# MCXC444 register map
Vendor: NXP Semiconductors; Series: MCX; File version: 1.6
CPU: CM0PLUS r0p0, little endian, no MPU, no FPU, VTOR, 2 interrupt priority bits
Registers are 32-bit, read-write, reset 0x0 unless marked. A register's access mark holds for its fields unless they carry their own. Offsets are from the block's base; [hi:lo] are bit positions; {n}, {i} and the like mark numbered series; 'fields as' and 'values as' point back to an identical list.

## PORTA — Pin Control and Interrupts
Base 0x40049000; register names take the prefix PORTA_
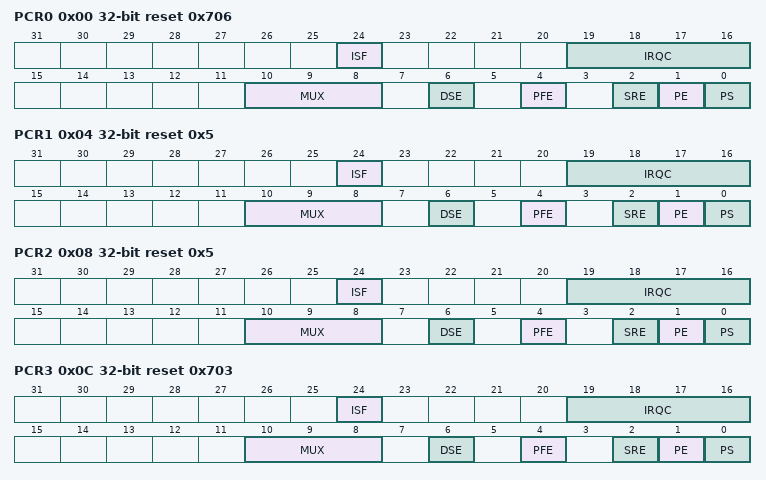
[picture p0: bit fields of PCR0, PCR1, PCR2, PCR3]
0x00 PCR0 reset 0x706 — Pin Control Register n
  [24] ISF — Interrupt Status Flag
    0=b0 (Configured interrupt is not detected.); 1=b1 (Configured interrupt is detected. If the pin is configured to generate a DMA request, then the corresponding flag will be cleared automatically at the completion of the requested DMA transfer. Otherwise, the flag remains set until a logic 1 is written to the flag. If the pin is configured for a level sensitive interrupt and the pin remains asserted, then the flag is set again immediately after it is cleared.)
  [19:16] IRQC — Interrupt Configuration
    0=b0000 (Interrupt/DMA request disabled.); 1=b0001 (DMA request on rising edge.); 2=b0010 (DMA request on falling edge.); 3=b0011 (DMA request on either edge.); 8=b1000 (Interrupt when logic 0.); 9=b1001 (Interrupt on rising-edge.); 10=b1010 (Interrupt on falling-edge.); 11=b1011 (Interrupt on either edge.); 12=b1100 (Interrupt when logic 1.)
  [10:8] MUX — Pin Mux Control
    0=b000 (Pin disabled (analog).); 1=b001 (Alternative 1 (GPIO).); 2=b010 (Alternative 2 (chip-specific).); 3=b011 (Alternative 3 (chip-specific).); 4=b100 (Alternative 4 (chip-specific).); 5=b101 (Alternative 5 (chip-specific).); 6=b110 (Alternative 6 (chip-specific).); 7=b111 (Alternative 7 (chip-specific).)
  [6] DSE ro — Drive Strength Enable
    0=b0 (Low drive strength is configured on the corresponding pin, if pin is configured as a digital output.); 1=b1 (High drive strength is configured on the corresponding pin, if pin is configured as a digital output.)
  [4] PFE ro — Passive Filter Enable
    0=b0 (Passive input filter is disabled on the corresponding pin.); 1=b1 (Passive input filter is enabled on the corresponding pin, if the pin is configured as a digital input. Refer to the device data sheet for filter characteristics.)
  [2] SRE — Slew Rate Enable
    0=b0 (Fast slew rate is configured on the corresponding pin, if the pin is configured as a digital output.); 1=b1 (Slow slew rate is configured on the corresponding pin, if the pin is configured as a digital output.)
  [1] PE — Pull Enable
    0=b0 (Internal pullup or pulldown resistor is not enabled on the corresponding pin.); 1=b1 (Internal pullup or pulldown resistor is enabled on the corresponding pin, if the pin is configured as a digital input.)
  [0] PS — Pull Select
    0=b0 (Internal pulldown resistor is enabled on the corresponding pin, if the corresponding PE field is set.); 1=b1 (Internal pullup resistor is enabled on the corresponding pin, if the corresponding PE field is set.)
0x04 PCR1 reset 0x5 — Pin Control Register n
  fields as PCR0
0x08 PCR2 reset 0x5 — Pin Control Register n
  fields as PCR0
0x0C PCR3 reset 0x703 — Pin Control Register n
  fields as PCR0
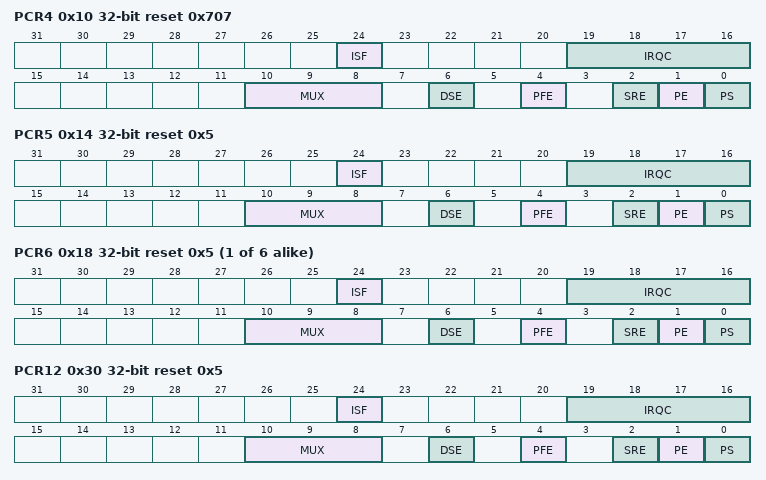
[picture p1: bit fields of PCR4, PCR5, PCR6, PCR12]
0x10 PCR4 reset 0x707 — Pin Control Register n
  [24] ISF — Interrupt Status Flag
    values as PCR0.ISF
  [19:16] IRQC — Interrupt Configuration
    values as PCR0.IRQC
  [10:8] MUX — Pin Mux Control
    values as PCR0.MUX
  [6] DSE ro — Drive Strength Enable
    values as PCR0.DSE
  [4] PFE — Passive Filter Enable
    values as PCR0.PFE
  [2] SRE — Slew Rate Enable
    values as PCR0.SRE
  [1] PE — Pull Enable
    values as PCR0.PE
  [0] PS — Pull Select
    values as PCR0.PS
0x14 PCR5 reset 0x5 — Pin Control Register n
  fields as PCR0
{0x0+4i} PCR{i} reset 0x5 (i=6..11) — Pin Control Register n
  [24] ISF — Interrupt Status Flag
    values as PCR0.ISF
  [19:16] IRQC — Interrupt Configuration
    values as PCR0.IRQC
  [10:8] MUX — Pin Mux Control
    values as PCR0.MUX
  [6] DSE ro — Drive Strength Enable
    values as PCR0.DSE
  [4] PFE ro — Passive Filter Enable
    values as PCR0.PFE
  [2] SRE ro — Slew Rate Enable
    values as PCR0.SRE
  [1] PE ro — Pull Enable
    values as PCR0.PE
  [0] PS ro — Pull Select
    values as PCR0.PS
0x30 PCR12 reset 0x5 — Pin Control Register n
  fields as PCR0
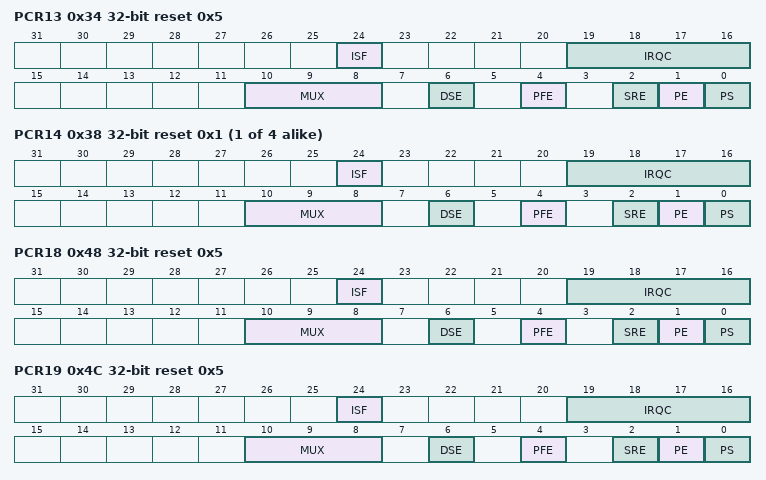
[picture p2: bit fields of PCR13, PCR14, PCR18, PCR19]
0x34 PCR13 reset 0x5 — Pin Control Register n
  fields as PCR0
{0x0+4i} PCR{i} reset 0x1 (i=14..17) — Pin Control Register n
  fields as PCR6
0x48 PCR18 reset 0x5 — Pin Control Register n
  fields as PCR0
0x4C PCR19 reset 0x5 — Pin Control Register n
  fields as PCR0
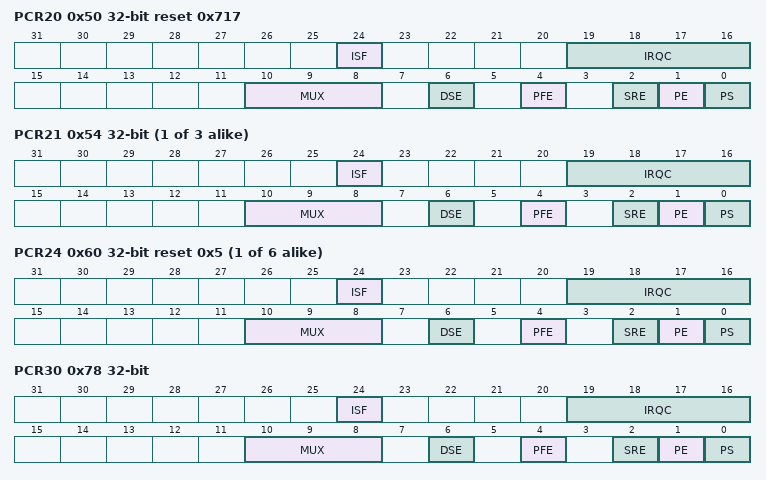
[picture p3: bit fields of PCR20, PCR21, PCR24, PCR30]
0x50 PCR20 reset 0x717 — Pin Control Register n
  fields as PCR4
{0x0+4i} PCR{i} (i=21..23) — Pin Control Register n
  fields as PCR6
{0x0+4i} PCR{i} reset 0x5 (i=24..29) — Pin Control Register n
  fields as PCR6
0x78 PCR30 — Pin Control Register n
  fields as PCR6
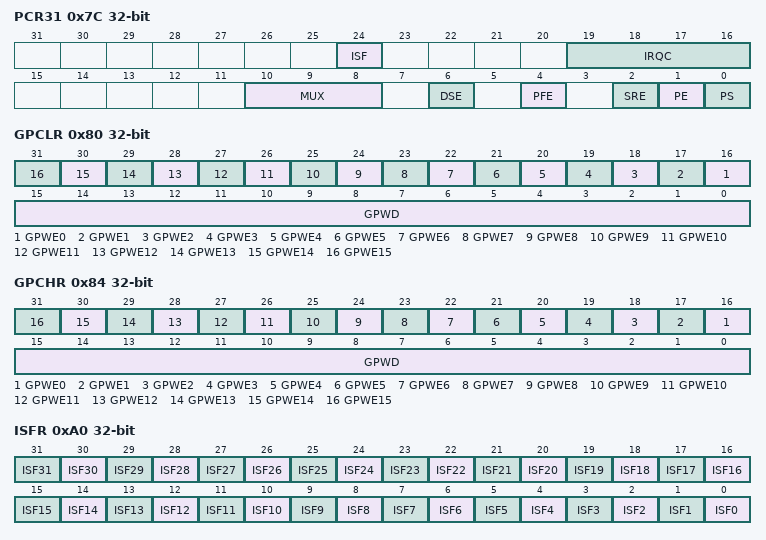
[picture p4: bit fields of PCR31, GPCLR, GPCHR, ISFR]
0x7C PCR31 — Pin Control Register n
  fields as PCR6
0x80 GPCLR — Global Pin Control Low Register
  [n+16] GPWE{n} (n=0..15) — Global Pin Write Enable
    0=b0000000000000000 (Corresponding Pin Control Register is not updated with the value in GPWD.); 1=b0000000000000001 (Corresponding Pin Control Register is updated with the value in GPWD.)
  [15:0] GPWD — Global Pin Write Data
0x84 GPCHR — Global Pin Control High Register
  fields as GPCLR
0xA0 ISFR — Interrupt Status Flag Register
  [all] fields
    0=b00000000000000000000000000000000 (Configured interrupt is not detected.); 1=b00000000000000000000000000000001 (Configured interrupt is detected. If the pin is configured to generate a DMA request, then the corresponding flag will be cleared automatically at the completion of the requested DMA transfer. Otherwise, the flag remains set until a logic 1 is written to the flag. If the pin is configured for a level sensitive interrupt and the pin remains asserted, then the flag is set again immediately after it is cleared.)
  [n] ISF{n} (n=0..31) — Interrupt Status Flag
